# STM32U385 register map
File version: 1.0
CPU: CM33 r0p1, little endian, MPU, FPU, 4 interrupt priority bits
Registers are 32-bit, read-write, reset 0x0 unless marked. A register's access mark holds for its fields unless they carry their own. Offsets are from the block's base; [hi:lo] are bit positions.

## GTZC1_TZIC — GTZC1_TZIC Address block
Base 0x40032800
Same registers: SEC_GTZC1_TZIC 0x50032800
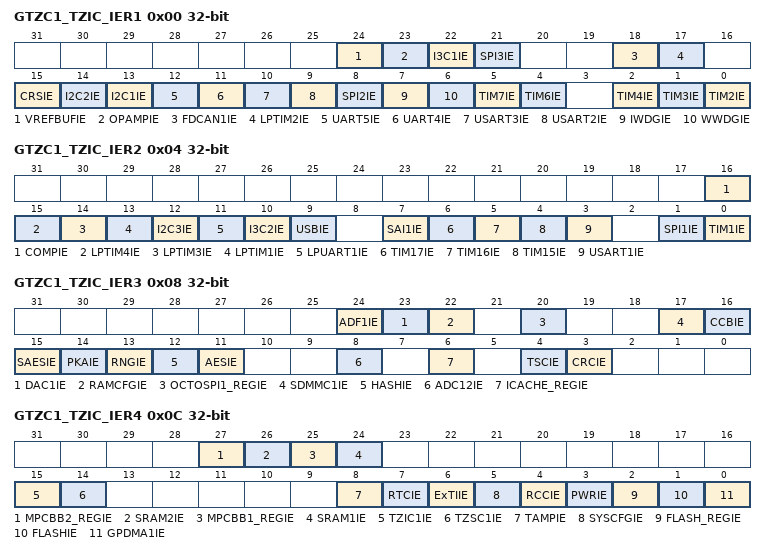
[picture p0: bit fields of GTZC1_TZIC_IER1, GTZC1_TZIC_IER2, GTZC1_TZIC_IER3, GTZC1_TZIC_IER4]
0x00 GTZC1_TZIC_IER1 — GTZC1 TZIC interrupt enable register 1
  [all] fields
    0=interrupt disabled; 1=interrupt enabled
  [24] VREFBUFIE — 0: interrupt disabled 1: interrupt enabled
  [23] OPAMPIE — 0: interrupt disabled 1: interrupt enabled
  [22] I3C1IE — 0: interrupt disabled 1: interrupt enabled
  [21] SPI3IE — 0: interrupt disabled 1: interrupt enabled
  [18] FDCAN1IE — 0: interrupt disabled 1: interrupt enabled
  [17] LPTIM2IE — 0: interrupt disabled 1: interrupt enabled
  [15] CRSIE — 0: interrupt disabled 1: interrupt enabled
  [14] I2C2IE — 0: interrupt disabled 1: interrupt enabled
  [13] I2C1IE — 0: interrupt disabled 1: interrupt enabled
  [12] UART5IE — 0: interrupt disabled 1: interrupt enabled
  [11] UART4IE — 0: interrupt disabled 1: interrupt enabled
  [10] USART3IE — 0: interrupt disabled 1: interrupt enabled
  [9] USART2IE — 0: interrupt disabled 1: interrupt enabled
  [8] SPI2IE — 0: interrupt disabled 1: interrupt enabled
  [7] IWDGIE — 0: interrupt disabled 1: interrupt enabled
  [6] WWDGIE — 0: interrupt disabled 1: interrupt enabled
  [5] TIM7IE — 0: interrupt disabled 1: interrupt enabled
  [4] TIM6IE — 0: interrupt disabled 1: interrupt enabled
  [2] TIM4IE — 0: interrupt disabled 1: interrupt enabled
  [1] TIM3IE — 0: interrupt disabled 1: interrupt enabled
  [0] TIM2IE — 0: interrupt disabled 1: interrupt enabled
0x04 GTZC1_TZIC_IER2 — GTZC1 TZIC interrupt enable register 2
  [all] fields
    0=interrupt disabled; 1=interrupt enabled
  [16] COMPIE — 0: interrupt disabled 1: interrupt enabled
  [15] LPTIM4IE — 0: interrupt disabled 1: interrupt enabled
  [14] LPTIM3IE — 0: interrupt disabled 1: interrupt enabled
  [13] LPTIM1IE — 0: interrupt disabled 1: interrupt enabled
  [12] I2C3IE — 0: interrupt disabled 1: interrupt enabled
  [11] LPUART1IE — 0: interrupt disabled 1: interrupt enabled
  [10] I3C2IE — 0: interrupt disabled 1: interrupt enabled
  [9] USBIE — 0: interrupt disabled 1: interrupt enabled
  [7] SAI1IE — 0: interrupt disabled 1: interrupt enabled
  [6] TIM17IE — 0: interrupt disabled 1: interrupt enabled
  [5] TIM16IE — 0: interrupt disabled 1: interrupt enabled
  [4] TIM15IE — 0: interrupt disabled 1: interrupt enabled
  [3] USART1IE — 0: interrupt disabled 1: interrupt enabled
  [1] SPI1IE — 0: interrupt disabled 1: interrupt enabled
  [0] TIM1IE — 0: interrupt disabled 1: interrupt enabled
0x08 GTZC1_TZIC_IER3 — GTZC1 TZIC interrupt enable register 3
  [all] fields
    0=interrupt disabled; 1=interrupt enabled
  [24] ADF1IE — 0: interrupt disabled 1: interrupt enabled
  [23] DAC1IE — 0: interrupt disabled 1: interrupt enabled
  [22] RAMCFGIE — 0: interrupt disabled 1: interrupt enabled
  [20] OCTOSPI1_REGIE — 0: interrupt disabled 1: interrupt enabled
  [17] SDMMC1IE — 0: interrupt disabled 1: interrupt enabled
  [16] CCBIE — 0: interrupt disabled 1: interrupt enabled
  [15] SAESIE — 0: interrupt disabled 1: interrupt enabled
  [14] PKAIE — 0: interrupt disabled 1: interrupt enabled
  [13] RNGIE — 0: interrupt disabled 1: interrupt enabled
  [12] HASHIE — 0: interrupt disabled 1: interrupt enabled
  [11] AESIE — 0: interrupt disabled 1: interrupt enabled
  [8] ADC12IE — 0: interrupt disabled 1: interrupt enabled
  [6] ICACHE_REGIE — 0: interrupt disabled 1: interrupt enabled
  [4] TSCIE — 0: interrupt disabled 1: interrupt enabled
  [3] CRCIE — 0: interrupt disabled 1: interrupt enabled
0x0C GTZC1_TZIC_IER4 — GTZC1 TZIC interrupt enable register 4
  [27] MPCBB2_REGIE — 0: interrupt disabled 1: interrupt enabled
    0=interrupt disabled; 1=interrupt enabled
  [26] SRAM2IE — 0: interrupt disabled 1: interrupt enabled
    0=interrupt disabled; 1=interrupt enabled
  [25] MPCBB1_REGIE — 0: interrupt disabled 1: interrupt enabled
    0=interrupt disabled; 1=interrupt enabled
  [24] SRAM1IE — 0: interrupt disabled 1: interrupt enabled
    0=interrupt disabled; 1=interrupt enabled
  [15] TZIC1IE — 0: interrupt disabled 1: interrupt enabled
    0=interrupt disabled; 1=interrupt enabled
  [14] TZSC1IE — 0: interrupt disabled 1: interrupt enabled
    0=interrupt disabled; 1=interrupt enabled
  [8] TAMPIE — 0: interrupt disabled 1: interrupt enabled
    0=interrupt disabled; 1=interrupt enabled
  [7] RTCIE — 0: interrupt disabled 1: interrupt enabled
    0=interrupt disabled; 1=interrupt enabled
  [6] ExTIIE — 0: interrupt disabled 1: interrupt enabled
    0=interrupt disabled; 1=interrupt enabled
  [5] SYSCFGIE — 0: interrupt disabled 1: interrupt enabled
    0=interrupt disabled; 1=interrupt enabled
  [4] RCCIE — 0: interrupt disabled 1: interrupt enabled
    0=interrupt disabled; 1=interrupt enabled
  [3] PWRIE — 0: interrupt disabled 1: interrupt enabled
    0=interrupt disabled; 1=interrupt enabled
  [2] FLASH_REGIE — Illegal access interrupt enable for FLASH registers
    0=Interrupt disabled; 1=Interrupt enabled
  [1] FLASHIE — Illegal access interrupt enable for FLASH memory
    0=Interrupt disabled; 1=Interrupt enabled
  [0] GPDMA1IE — 0: interrupt disabled 1: interrupt enabled
    0=interrupt disabled; 1=interrupt enabled
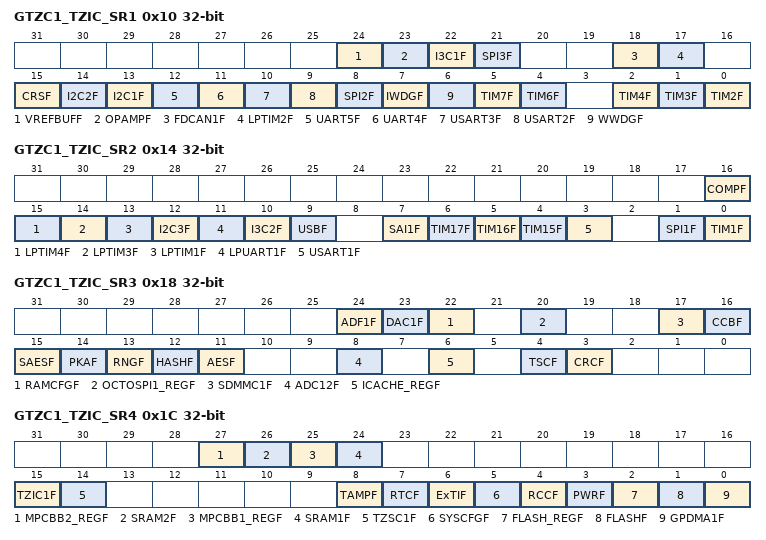
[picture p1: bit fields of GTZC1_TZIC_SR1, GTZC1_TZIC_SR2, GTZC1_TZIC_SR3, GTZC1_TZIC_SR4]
0x10 GTZC1_TZIC_SR1 — GTZC1 TZIC status register 1
  [all] fields
    0=no illegal access event; 1=illegal access event
  [24] VREFBUFF — 0: no illegal access event 1: illegal access event
  [23] OPAMPF — 0: no illegal access event 1: illegal access event
  [22] I3C1F — 0: no illegal access event 1: illegal access event
  [21] SPI3F — 0: no illegal access event 1: illegal access event
  [18] FDCAN1F — 0: no illegal access event 1: illegal access event
  [17] LPTIM2F — 0: no illegal access event 1: illegal access event
  [15] CRSF — 0: no illegal access event 1: illegal access event
  [14] I2C2F — 0: no illegal access event 1: illegal access event
  [13] I2C1F — 0: no illegal access event 1: illegal access event
  [12] UART5F — 0: no illegal access event 1: illegal access event
  [11] UART4F — 0: no illegal access event 1: illegal access event
  [10] USART3F — 0: no illegal access event 1: illegal access event
  [9] USART2F — 0: no illegal access event 1: illegal access event
  [8] SPI2F — 0: no illegal access event 1: illegal access event
  [7] IWDGF — 0: no illegal access event 1: illegal access event
  [6] WWDGF — 0: no illegal access event 1: illegal access event
  [5] TIM7F — 0: no illegal access event 1: illegal access event
  [4] TIM6F — 0: no illegal access event 1: illegal access event
  [2] TIM4F — 0: no illegal access event 1: illegal access event
  [1] TIM3F — 0: no illegal access event 1: illegal access event
  [0] TIM2F — 0: no illegal access event 1: illegal access event
0x14 GTZC1_TZIC_SR2 — GTZC1 TZIC status register 2
  [all] fields
    0=no illegal access event; 1=illegal access event
  [16] COMPF — 0: no illegal access event 1: illegal access event
  [15] LPTIM4F — 0: no illegal access event 1: illegal access event
  [14] LPTIM3F — 0: no illegal access event 1: illegal access event
  [13] LPTIM1F — 0: no illegal access event 1: illegal access event
  [12] I2C3F — 0: no illegal access event 1: illegal access event
  [11] LPUART1F — 0: no illegal access event 1: illegal access event
  [10] I3C2F — 0: no illegal access event 1: illegal access event
  [9] USBF — 0: no illegal access event 1: illegal access event
  [7] SAI1F — 0: no illegal access event 1: illegal access event
  [6] TIM17F — 0: no illegal access event 1: illegal access event
  [5] TIM16F — 0: no illegal access event 1: illegal access event
  [4] TIM15F — 0: no illegal access event 1: illegal access event
  [3] USART1F — 0: no illegal access event 1: illegal access event
  [1] SPI1F — 0: no illegal access event 1: illegal access event
  [0] TIM1F — 0: no illegal access event 1: illegal access event
0x18 GTZC1_TZIC_SR3 — GTZC1 TZIC status register 3
  [all] fields
    0=no illegal access event; 1=illegal access event
  [24] ADF1F — 0: no illegal access event 1: illegal access event
  [23] DAC1F — 0: no illegal access event 1: illegal access event
  [22] RAMCFGF — 0: no illegal access event 1: illegal access event
  [20] OCTOSPI1_REGF — 0: no illegal access event 1: illegal access event
  [17] SDMMC1F — 0: no illegal access event 1: illegal access event
  [16] CCBF — 0: no illegal access event 1: illegal access event
  [15] SAESF — 0: no illegal access event 1: illegal access event
  [14] PKAF — 0: no illegal access event 1: illegal access event
  [13] RNGF — 0: no illegal access event 1: illegal access event
  [12] HASHF — 0: no illegal access event 1: illegal access event
  [11] AESF — 0: no illegal access event 1: illegal access event
  [8] ADC12F — 0: no illegal access event 1: illegal access event
  [6] ICACHE_REGF — 0: no illegal access event 1: illegal access event
  [4] TSCF — 0: no illegal access event 1: illegal access event
  [3] CRCF — 0: no illegal access event 1: illegal access event
0x1C GTZC1_TZIC_SR4 — GTZC1 TZIC status register 4
  [27] MPCBB2_REGF — 0: no illegal access event 1: illegal access event
    0=no illegal access event; 1=illegal access event
  [26] SRAM2F — 0: no illegal access event 1: illegal access event
    0=no illegal access event; 1=illegal access event
  [25] MPCBB1_REGF — 0: no illegal access event 1: illegal access event
    0=no illegal access event; 1=illegal access event
  [24] SRAM1F — 0: no illegal access event 1: illegal access event
    0=no illegal access event; 1=illegal access event
  [15] TZIC1F — 0: no illegal access event 1: illegal access event
    0=no illegal access event; 1=illegal access event
  [14] TZSC1F — 0: no illegal access event 1: illegal access event
    0=no illegal access event; 1=illegal access event
  [8] TAMPF — 0: no illegal access event 1: illegal access event
    0=no illegal access event; 1=illegal access event
  [7] RTCF — 0: no illegal access event 1: illegal access event
    0=no illegal access event; 1=illegal access event
  [6] ExTIF — 0: no illegal access event 1: illegal access event
    0=no illegal access event; 1=illegal access event
  [5] SYSCFGF — 0: no illegal access event 1: illegal access event
    0=no illegal access event; 1=illegal access event
  [4] RCCF — 0: no illegal access event 1: illegal access event
    0=no illegal access event; 1=illegal access event
  [3] PWRF — 0: no illegal access event 1: illegal access event
    0=no illegal access event; 1=illegal access event
  [2] FLASH_REGF — Illegal access flag for FLASH registers
    0=No illegal access event; 1=Illegal access event
  [1] FLASHF — Illegal access flag for FLASH memory
    0=No illegal access event; 1=Illegal access event
  [0] GPDMA1F — 0: no illegal access event 1: illegal access event
    0=no illegal access event; 1=illegal access event
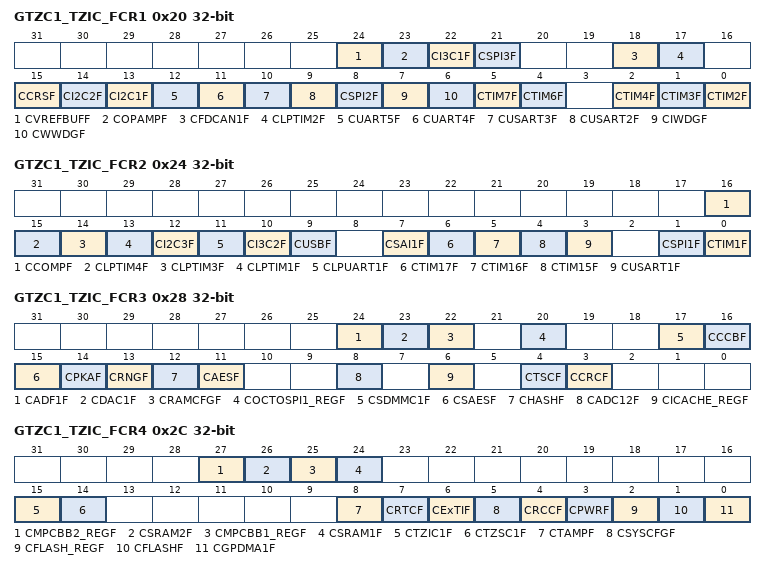
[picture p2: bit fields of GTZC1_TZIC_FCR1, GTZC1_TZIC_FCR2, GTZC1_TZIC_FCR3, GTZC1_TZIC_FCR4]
0x20 GTZC1_TZIC_FCR1 — GTZC1 TZIC flag clear register 1
  [all] fields
    0=no action; 1=status flag cleared
  [24] CVREFBUFF — 0: no action 1: status flag cleared
  [23] COPAMPF — 0: no action 1: status flag cleared
  [22] CI3C1F — 0: no action 1: status flag cleared
  [21] CSPI3F — 0: no action 1: status flag cleared
  [18] CFDCAN1F — 0: no action 1: status flag cleared
  [17] CLPTIM2F — 0: no action 1: status flag cleared
  [15] CCRSF — 0: no action 1: status flag cleared
  [14] CI2C2F — 0: no action 1: status flag cleared
  [13] CI2C1F — 0: no action 1: status flag cleared
  [12] CUART5F — 0: no action 1: status flag cleared
  [11] CUART4F — 0: no action 1: status flag cleared
  [10] CUSART3F — 0: no action 1: status flag cleared
  [9] CUSART2F — 0: no action 1: status flag cleared
  [8] CSPI2F — 0: no action 1: status flag cleared
  [7] CIWDGF — 0: no action 1: status flag cleared
  [6] CWWDGF — 0: no action 1: status flag cleared
  [5] CTIM7F — 0: no action 1: status flag cleared
  [4] CTIM6F — 0: no action 1: status flag cleared
  [2] CTIM4F — 0: no action 1: status flag cleared
  [1] CTIM3F — 0: no action 1: status flag cleared
  [0] CTIM2F — 0: no action 1: status flag cleared
0x24 GTZC1_TZIC_FCR2 — GTZC1 TZIC flag clear register 2
  [all] fields
    0=no action; 1=status flag cleared
  [16] CCOMPF — 0: no action 1: status flag cleared
  [15] CLPTIM4F — 0: no action 1: status flag cleared
  [14] CLPTIM3F — 0: no action 1: status flag cleared
  [13] CLPTIM1F — 0: no action 1: status flag cleared
  [12] CI2C3F — 0: no action 1: status flag cleared
  [11] CLPUART1F — 0: no action 1: status flag cleared
  [10] CI3C2F — 0: no action 1: status flag cleared
  [9] CUSBF — 0: no action 1: status flag cleared
  [7] CSAI1F — 0: no action 1: status flag cleared
  [6] CTIM17F — 0: no action 1: status flag cleared
  [5] CTIM16F — 0: no action 1: status flag cleared
  [4] CTIM15F — 0: no action 1: status flag cleared
  [3] CUSART1F — 0: no action 1: status flag cleared
  [1] CSPI1F — 0: no action 1: status flag cleared
  [0] CTIM1F — 0: no action 1: status flag cleared
0x28 GTZC1_TZIC_FCR3 — GTZC1 TZIC flag clear register 3
  [all] fields
    0=no action; 1=status flag cleared
  [24] CADF1F — 0: no action 1: status flag cleared
  [23] CDAC1F — 0: no action 1: status flag cleared
  [22] CRAMCFGF — 0: no action 1: status flag cleared
  [20] COCTOSPI1_REGF — 0: no action 1: status flag cleared
  [17] CSDMMC1F — 0: no action 1: status flag cleared
  [16] CCCBF — 0: no action 1: status flag cleared
  [15] CSAESF — 0: no action 1: status flag cleared
  [14] CPKAF — 0: no action 1: status flag cleared
  [13] CRNGF — 0: no action 1: status flag cleared
  [12] CHASHF — 0: no action 1: status flag cleared
  [11] CAESF — 0: no action 1: status flag cleared
  [8] CADC12F — 0: no action 1: status flag cleared
  [6] CICACHE_REGF — 0: no action 1: status flag cleared
  [4] CTSCF — 0: no action 1: status flag cleared
  [3] CCRCF — 0: no action 1: status flag cleared
0x2C GTZC1_TZIC_FCR4 — GTZC1 TZIC flag clear register 4
  [27] CMPCBB2_REGF — 0: no action 1: status flag cleared
    0=no action; 1=status flag cleared
  [26] CSRAM2F — 0: no action 1: status flag cleared
    0=no action; 1=status flag cleared
  [25] CMPCBB1_REGF — 0: no action 1: status flag cleared
    0=no action; 1=status flag cleared
  [24] CSRAM1F — 0: no action 1: status flag cleared
    0=no action; 1=status flag cleared
  [15] CTZIC1F — 0: no action 1: status flag cleared
    0=no action; 1=status flag cleared
  [14] CTZSC1F — 0: no action 1: status flag cleared
    0=no action; 1=status flag cleared
  [8] CTAMPF — 0: no action 1: status flag cleared
    0=no action; 1=status flag cleared
  [7] CRTCF — 0: no action 1: status flag cleared
    0=no action; 1=status flag cleared
  [6] CExTIF — 0: no action 1: status flag cleared
    0=no action; 1=status flag cleared
  [5] CSYSCFGF — 0: no action 1: status flag cleared
    0=no action; 1=status flag cleared
  [4] CRCCF — 0: no action 1: status flag cleared
    0=no action; 1=status flag cleared
  [3] CPWRF — 0: no action 1: status flag cleared
    0=no action; 1=status flag cleared
  [2] CFLASH_REGF — Clear the illegal access flag for FLASH registers
    0=No action; 1=Status flag cleared
  [1] CFLASHF — Clear the illegal access flag for FLASH memory
    0=No action; 1=Status flag cleared
  [0] CGPDMA1F — 0: no action 1: status flag cleared
    0=no action; 1=status flag cleared
